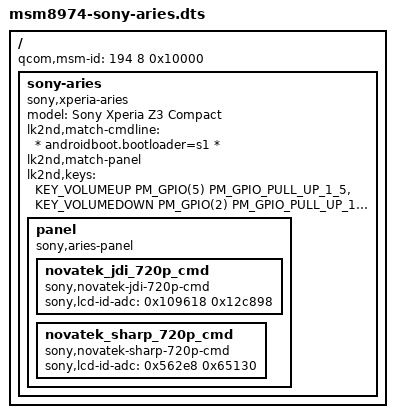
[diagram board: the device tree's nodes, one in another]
// SPDX-License-Identifier: GPL-2.0-only

/dts-v1/;

#include <skeleton.dtsi>
#include <lk2nd.h>

/ {
	qcom,msm-id = <194 8 0x10000>;
	sony-aries {
		model = "Sony Xperia Z3 Compact";
		compatible = "sony,xperia-aries", "qcom,msm8974", "lk2nd,device";
		lk2nd,match-cmdline = "* androidboot.bootloader=s1 *";
		lk2nd,match-panel;
		lk2nd,keys =
			<KEY_VOLUMEUP   PM_GPIO(5) PM_GPIO_PULL_UP_1_5>,
			<KEY_VOLUMEDOWN PM_GPIO(2) PM_GPIO_PULL_UP_1_5>;
		panel {
			compatible = "sony,aries-panel";
			
			novatek_jdi_720p_cmd {
				compatible = "sony,novatek-jdi-720p-cmd";
				sony,lcd-id-adc = <0x109618 0x12c898>;
			};
			
			novatek_sharp_720p_cmd {
				compatible = "sony,novatek-sharp-720p-cmd";
				sony,lcd-id-adc = <0x562e8 0x65130>;
			};
		};
	};
};

#include "msm8974pro-ac-shinano_aries_display.dtsi"

